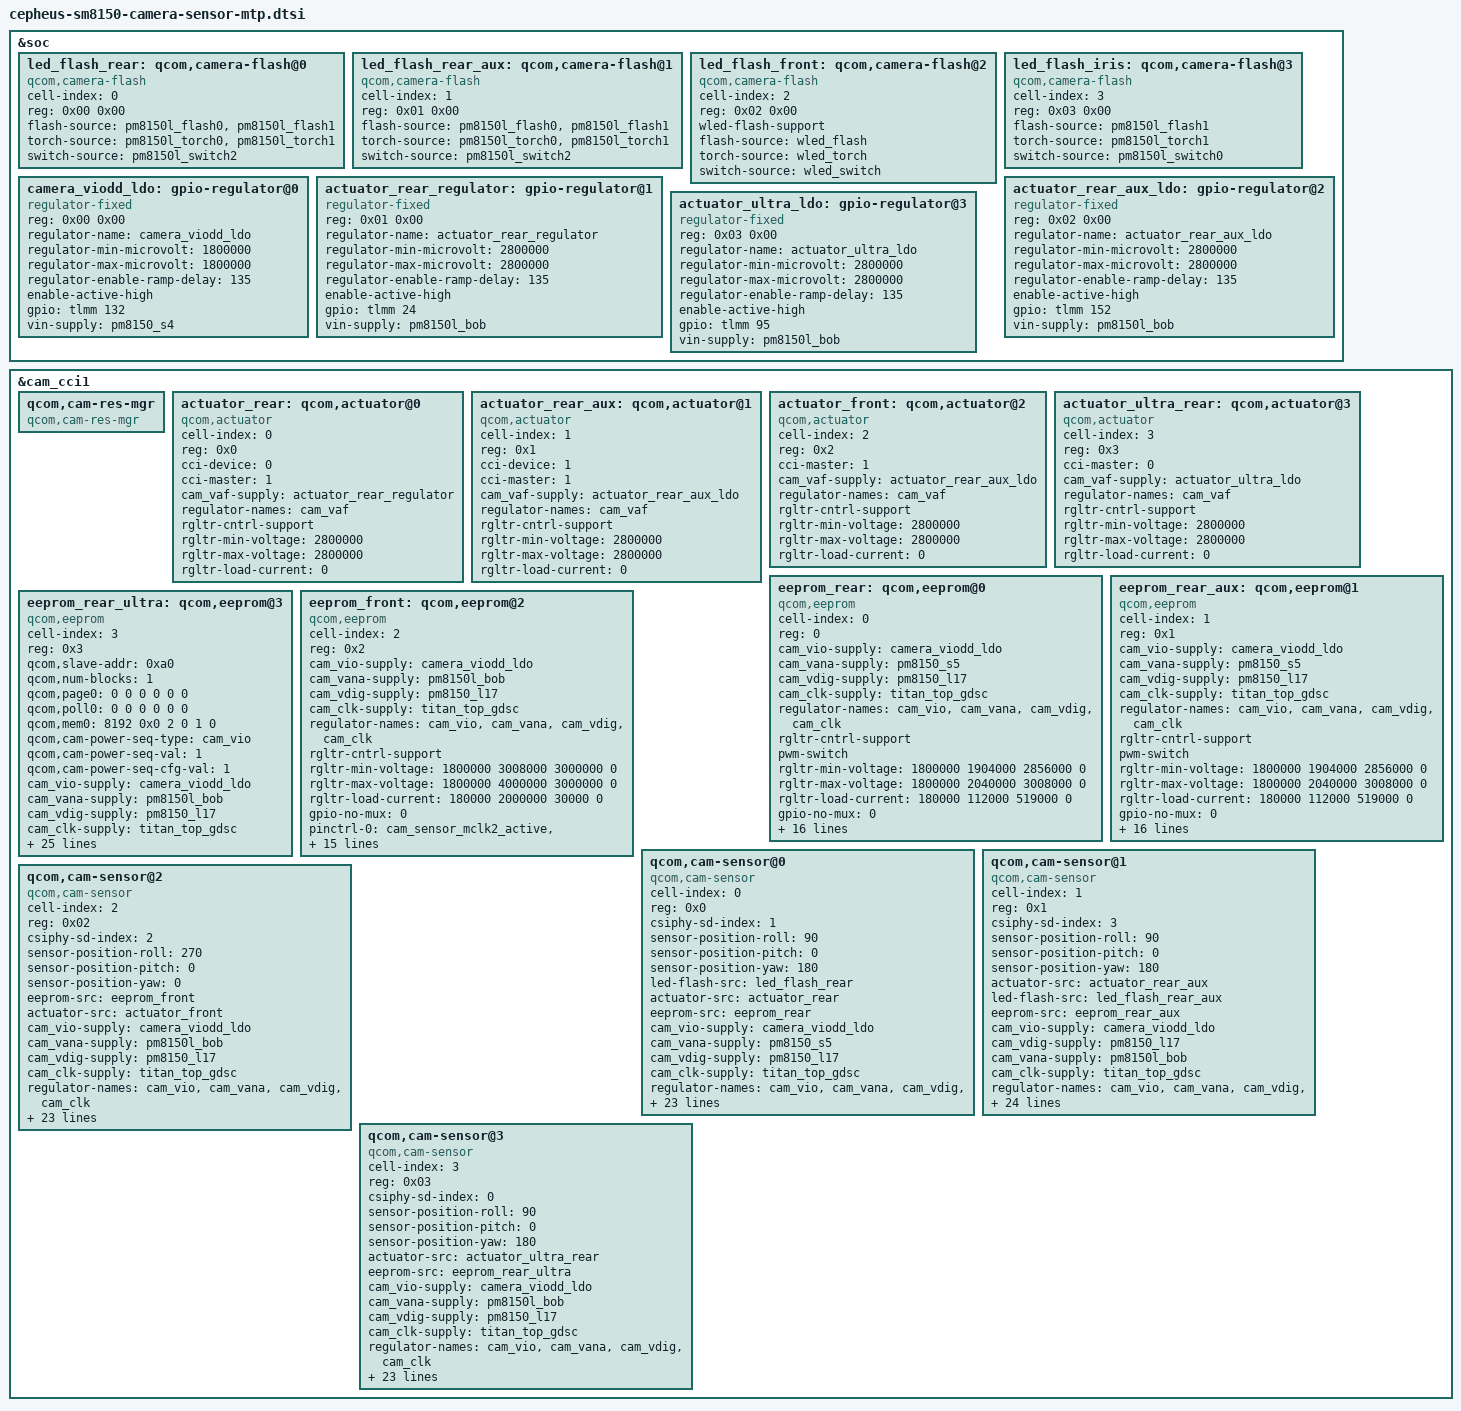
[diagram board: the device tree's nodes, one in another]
/*
 * Copyright (c) 2018, The Linux Foundation. All rights reserved.
 * Copyright (C) 2019 XiaoMi, Inc.
 *
 * This program is free software; you can redistribute it and/or modify
 * it under the terms of the GNU General Public License version 2 and
 * only version 2 as published by the Free Software Foundation.
 *
 * This program is distributed in the hope that it will be useful,
 * but WITHOUT ANY WARRANTY; without even the implied warranty of
 * MERCHANTABILITY or FITNESS FOR A PARTICULAR PURPOSE.  See the
 * GNU General Public License for more details.
 */

&soc {
	led_flash_rear: qcom,camera-flash@0 {
		cell-index = <0>;
		reg = <0x00 0x00>;
		compatible = "qcom,camera-flash";
		flash-source = <&pm8150l_flash0 &pm8150l_flash1>;
		torch-source = <&pm8150l_torch0 &pm8150l_torch1>;
		switch-source = <&pm8150l_switch2>;
		status = "ok";
	};

	led_flash_rear_aux: qcom,camera-flash@1 {
		cell-index = <1>;
		reg = <0x01 0x00>;
		compatible = "qcom,camera-flash";
		flash-source = <&pm8150l_flash0 &pm8150l_flash1>;
		torch-source = <&pm8150l_torch0 &pm8150l_torch1>;
		switch-source = <&pm8150l_switch2>;
		status = "ok";
	};

	led_flash_front: qcom,camera-flash@2 {
		cell-index = <2>;
		reg = <0x02 0x00>;
		compatible = "qcom,camera-flash";
		wled-flash-support;
		flash-source = <&wled_flash>;
		torch-source = <&wled_torch>;
		switch-source = <&wled_switch>;
		status = "ok";
	};

	led_flash_iris: qcom,camera-flash@3 {
		cell-index = <3>;
		reg = <0x03 0x00>;
		compatible = "qcom,camera-flash";
		flash-source = <&pm8150l_flash1>;
		torch-source = <&pm8150l_torch1>;
		switch-source = <&pm8150l_switch0>;
		status = "ok";
	};

	camera_viodd_ldo: gpio-regulator@0 {
		compatible = "regulator-fixed";
		reg = <0x00 0x00>;
		regulator-name = "camera_viodd_ldo";
		regulator-min-microvolt = <1800000>;
		regulator-max-microvolt = <1800000>;
		regulator-enable-ramp-delay = <135>;
		enable-active-high;
		gpio = <&tlmm 132 0>;
		vin-supply = <&pm8150_s4>;
	};

	actuator_rear_regulator: gpio-regulator@1 {
		compatible = "regulator-fixed";
		reg = <0x01 0x00>;
		regulator-name = "actuator_rear_regulator";
		regulator-min-microvolt = <2800000>;
		regulator-max-microvolt = <2800000>;
		regulator-enable-ramp-delay = <135>;
		enable-active-high;
		gpio = <&tlmm 24 0>;
		vin-supply = <&pm8150l_bob>;
	};

	actuator_rear_aux_ldo: gpio-regulator@2 {
		compatible = "regulator-fixed";
		reg = <0x02 0x00>;
		regulator-name = "actuator_rear_aux_ldo";
		regulator-min-microvolt = <2800000>;
		regulator-max-microvolt = <2800000>;
		regulator-enable-ramp-delay = <135>;
		enable-active-high;
		gpio = <&tlmm 152 0>;
		vin-supply = <&pm8150l_bob>;
	};

	actuator_ultra_ldo: gpio-regulator@3 {
		compatible = "regulator-fixed";
		reg = <0x03 0x00>;
		regulator-name = "actuator_ultra_ldo";
		regulator-min-microvolt = <2800000>;
		regulator-max-microvolt = <2800000>;
		regulator-enable-ramp-delay = <135>;
		enable-active-high;
		gpio = <&tlmm 95 0>;
		vin-supply = <&pm8150l_bob>;
	};
};

&cam_cci1 {
	qcom,cam-res-mgr {
		compatible = "qcom,cam-res-mgr";
		status = "ok";
	};

	actuator_rear: qcom,actuator@0 {
		cell-index = <0>;
		reg = <0x0>;
		compatible = "qcom,actuator";
		cci-device = <0>;
		cci-master = <1>;
		cam_vaf-supply = <&actuator_rear_regulator>;
		regulator-names = "cam_vaf";
		rgltr-cntrl-support;
		rgltr-min-voltage = <2800000>;
		rgltr-max-voltage = <2800000>;
		rgltr-load-current = <0>;
	};

	actuator_rear_aux: qcom,actuator@1 {
		cell-index = <1>;
		reg = <0x1>;
		compatible = "qcom,actuator";
		cci-device = <1>;
		cci-master = <1>;
		cam_vaf-supply = <&actuator_rear_aux_ldo>;
		regulator-names = "cam_vaf";
		rgltr-cntrl-support;
		rgltr-min-voltage = <2800000>;
		rgltr-max-voltage = <2800000>;
		rgltr-load-current = <0>;
	};

	actuator_front: qcom,actuator@2 {
		cell-index = <2>;
		reg = <0x2>;
		compatible = "qcom,actuator";
		cci-master = <1>;
		cam_vaf-supply = <&actuator_rear_aux_ldo>;
		regulator-names = "cam_vaf";
		rgltr-cntrl-support;
		rgltr-min-voltage = <2800000>;
		rgltr-max-voltage = <2800000>;
		rgltr-load-current = <0>;
	};

	actuator_ultra_rear: qcom,actuator@3 {
		cell-index = <3>;
		reg = <0x3>;
		compatible = "qcom,actuator";
		cci-master = <0>;
		cam_vaf-supply = <&actuator_ultra_ldo>;
		regulator-names = "cam_vaf";
		rgltr-cntrl-support;
		rgltr-min-voltage = <2800000>;
		rgltr-max-voltage = <2800000>;
		rgltr-load-current = <0>;
	};

	eeprom_rear: qcom,eeprom@0 {
		cell-index = <0>;
		reg = <0>;
		compatible = "qcom,eeprom";
		cam_vio-supply = <&camera_viodd_ldo>;
		cam_vana-supply = <&pm8150_s5>;
		cam_vdig-supply = <&pm8150_l17>;
		cam_clk-supply = <&titan_top_gdsc>;
		regulator-names = "cam_vio", "cam_vana", "cam_vdig",
		      "cam_clk";
		rgltr-cntrl-support;
		pwm-switch;
		rgltr-min-voltage = <1800000 1904000 2856000 0>;
		rgltr-max-voltage = <1800000 2040000 3008000 0>;
		rgltr-load-current = <180000 112000 519000 0>;
		gpio-no-mux = <0>;
		pinctrl-names = "cam_default", "cam_suspend";
		pinctrl-0 = <&cam_sensor_mclk1_active
				&cam_sensor_active_rear>;
		pinctrl-1 = <&cam_sensor_mclk1_suspend
				&cam_sensor_suspend_rear>;
		gpios = <&tlmm 14 0>,
			<&tlmm 30 0>,
			<&tlmm 59 0>;
		gpio-reset = <1>;
		gpio-vdig = <2>;
		gpio-req-tbl-num = <0 1 2>;
		gpio-req-tbl-flags = <1 0 0>;
		gpio-req-tbl-label = "CAMIF_MCLK0",
					"CAM_RESET0",
					"CAM_VDIG0";
		sensor-mode = <0>;
		cci-master = <1>;
		status = "ok";
		clocks = <&clock_camcc CAM_CC_MCLK1_CLK>;
		clock-names = "cam_clk";
		clock-cntl-level = "turbo";
		clock-rates = <19200000>;
	};

	eeprom_rear_aux: qcom,eeprom@1 {
		cell-index = <1>;
		reg = <0x1>;
		compatible = "qcom,eeprom";
		cam_vio-supply = <&camera_viodd_ldo>;
		cam_vana-supply = <&pm8150_s5>;
		cam_vdig-supply = <&pm8150_l17>;
		cam_clk-supply = <&titan_top_gdsc>;
		regulator-names = "cam_vio", "cam_vana", "cam_vdig",
		      "cam_clk";
		rgltr-cntrl-support;
		pwm-switch;
		rgltr-min-voltage = <1800000 1904000 2856000 0>;
		rgltr-max-voltage = <1800000 2040000 3008000 0>;
		rgltr-load-current = <180000 112000 519000 0>;
		gpio-no-mux = <0>;
		pinctrl-names = "cam_default", "cam_suspend";
		pinctrl-0 = <&cam_sensor_mclk1_active
				&cam_sensor_active_rear>;
		pinctrl-1 = <&cam_sensor_mclk1_suspend
				&cam_sensor_suspend_rear>;
		gpios = <&tlmm 14 0>,
			<&tlmm 30 0>,
			<&tlmm 59 0>;
		gpio-reset = <1>;
		gpio-vdig = <2>;
		gpio-req-tbl-num = <0 1 2>;
		gpio-req-tbl-flags = <1 0 0>;
		gpio-req-tbl-label = "CAMIF_MCLK0",
					"CAM_RESET0",
					"CAM_VDIG0";
		sensor-mode = <0>;
		cci-master = <1>;
		status = "ok";
		clocks = <&clock_camcc CAM_CC_MCLK1_CLK>;
		clock-names = "cam_clk";
		clock-cntl-level = "turbo";
		clock-rates = <19200000>;
	};

	eeprom_rear_ultra: qcom,eeprom@3 {
		cell-index = <3>;
		reg = <0x3>;

		compatible = "qcom,eeprom";
		qcom,slave-addr = <0xa0>;
		qcom,num-blocks = <1>;
		qcom,page0 = <0 0 0 0 0 0 >;
		qcom,poll0 = <0 0 0 0 0 0>;
		qcom,mem0 = <8192 0x0 2 0 1 0>;
		qcom,cam-power-seq-type = "cam_vio";
		qcom,cam-power-seq-val = <1>;
		qcom,cam-power-seq-cfg-val = <1>;
		cam_vio-supply = <&camera_viodd_ldo>;
		cam_vana-supply = <&pm8150l_bob>;
		cam_vdig-supply = <&pm8150_l17>;
		cam_clk-supply = <&titan_top_gdsc>;
		regulator-names = "cam_vio", "cam_vana", "cam_vdig",
			"cam_clk";
		rgltr-cntrl-support;
		rgltr-min-voltage = <1800000 3008000 2856000 0>;
		rgltr-max-voltage = <1800000 4000000 3000000 0>;
		rgltr-load-current = <180000 2000000 300000 0>;
		gpio-no-mux = <0>;
		pinctrl-names = "cam_default", "cam_suspend";
		pinctrl-0 = <&cam_sensor_mclk0_active
				 &cam_sensor_active_iris>;
		pinctrl-1 = <&cam_sensor_mclk0_suspend
				 &cam_sensor_suspend_iris>;
		gpios = <&tlmm 13 0>,
			<&tlmm 28 0>,
			<&tlmm 94 0>;
		gpio-reset = <1>;
		gpio-vana = <2>;
		gpio-req-tbl-num = <0 1 2>;
		gpio-req-tbl-flags = <1 0 0>;
		gpio-req-tbl-label = "CAMIF_MCLK3",
				 "CAM_RESET3",
				 "CAM_VDIG3";
		sensor-position = <0>;
		sensor-mode = <0>;
		cci-device = <0>;
		cci-master = <0>;
		status = "ok";
		clocks = <&clock_camcc CAM_CC_MCLK0_CLK>;
		clock-names = "cam_clk";
		clock-cntl-level = "turbo";
		clock-rates = <19200000>;
	};

	eeprom_front: qcom,eeprom@2 {
		cell-index = <2>;
		reg = <0x2>;
		compatible = "qcom,eeprom";
		cam_vio-supply = <&camera_viodd_ldo>;
		cam_vana-supply = <&pm8150l_bob>;
		cam_vdig-supply = <&pm8150_l17>;
		cam_clk-supply = <&titan_top_gdsc>;
		regulator-names = "cam_vio", "cam_vana", "cam_vdig",
							"cam_clk";
		rgltr-cntrl-support;
		rgltr-min-voltage = <1800000 3008000 3000000 0>;
		rgltr-max-voltage = <1800000 4000000 3000000 0>;
		rgltr-load-current = <180000 2000000 30000 0>;
		gpio-no-mux = <0>;
		pinctrl-names = "cam_default", "cam_suspend";
		pinctrl-0 = <&cam_sensor_mclk2_active
						&cam_sensor_active_front>;
		pinctrl-1 = <&cam_sensor_mclk2_suspend
						&cam_sensor_suspend_front>;
		gpios = <&tlmm 15 0>,
			<&tlmm 54 0>,

			<&tlmm 118 0>;
		gpio-reset = <1>;
		gpio-req-tbl-num = <0 1>;
		gpio-req-tbl-flags = <1 0>;
		gpio-req-tbl-label = "CAMIF_MCLK2",
				"CAM_RESET2";
		sensor-position = <1>;
		sensor-mode = <0>;
		cci-device = <1>;
		cci-master = <1>;
		status = "ok";
		clocks = <&clock_camcc CAM_CC_MCLK2_CLK>;
		clock-names = "cam_clk";
		clock-cntl-level = "turbo";
		clock-rates = <19200000>;
	};

	qcom,cam-sensor@0 {
		cell-index = <0>;
		compatible = "qcom,cam-sensor";
		reg = <0x0>;
		csiphy-sd-index = <1>;
		sensor-position-roll = <90>;
		sensor-position-pitch = <0>;
		sensor-position-yaw = <180>;
		led-flash-src = <&led_flash_rear>;
		actuator-src = <&actuator_rear>;
		eeprom-src = <&eeprom_rear>;
		cam_vio-supply = <&camera_viodd_ldo>;
		cam_vana-supply = <&pm8150_s5>;
		cam_vdig-supply = <&pm8150_l17>;
		cam_clk-supply = <&titan_top_gdsc>;
		regulator-names = "cam_vio", "cam_vana", "cam_vdig",
			 "cam_clk";
		rgltr-cntrl-support;
		pwm-switch;
		rgltr-min-voltage = <1800000 1904000 2856000 0>;
		rgltr-max-voltage = <1800000 2040000 3008000 0>;
		rgltr-load-current = <180000 112000 519000 0>;
		gpio-no-mux = <0>;
		pinctrl-names = "cam_default", "cam_suspend";
		pinctrl-0 = <&cam_sensor_mclk1_active
				&cam_sensor_active_rear>;
		pinctrl-1 = <&cam_sensor_mclk1_suspend
				&cam_sensor_suspend_rear>;
		gpios = <&tlmm 14 0>,
			<&tlmm 30 0>,
			<&tlmm 59 0>;
		gpio-reset = <1>;
		gpio-vdig = <2>;
		gpio-req-tbl-num = <0 1 2>;
		gpio-req-tbl-flags = <1 0 0>;
		gpio-req-tbl-label = "CAMIF_MCLK0",
					"CAM_RESET0",
					"CAM_VDIG0";
		sensor-mode = <0>;
		cci-master = <1>;
		status = "ok";
		clocks = <&clock_camcc CAM_CC_MCLK1_CLK>;
		clock-names = "cam_clk";
		clock-cntl-level = "turbo";
		clock-rates = <19200000>;
	};


	qcom,cam-sensor@1 {
		cell-index = <1>;
		compatible = "qcom,cam-sensor";
		reg = <0x1>;
		csiphy-sd-index = <3>;
		sensor-position-roll = <90>;
		sensor-position-pitch = <0>;
		sensor-position-yaw = <180>;
		actuator-src = <&actuator_rear_aux>;
		led-flash-src = <&led_flash_rear_aux>;
		eeprom-src = <&eeprom_rear_aux>;
		cam_vio-supply = <&camera_viodd_ldo>;
		cam_vdig-supply = <&pm8150_l17>;
		cam_vana-supply = <&pm8150l_bob>;
		cam_clk-supply = <&titan_top_gdsc>;
		regulator-names = "cam_vio", "cam_vana", "cam_vdig",
			"cam_clk";
		rgltr-cntrl-support;
		pwm-switch;
		rgltr-min-voltage = <1800000 3008000 3000000 0>;
		rgltr-max-voltage = <1800000 4000000 3000000 0>;
		rgltr-load-current = <180000 2000000 300000 0>;
		gpio-no-mux = <0>;
		pinctrl-names = "cam_default", "cam_suspend";
		pinctrl-0 = <&cam_sensor_mclk3_active
				&cam_sensor_active_rear_aux>;
		pinctrl-1 = <&cam_sensor_mclk3_suspend
				&cam_sensor_suspend_rear_aux>;
		gpios = <&tlmm 16 0>,
			<&tlmm 23 0>,
			<&tlmm 29 0>;
		gpio-reset = <1>;
		gpio-vana = <2>;
		gpio-req-tbl-num = <0 1 2>;
		gpio-req-tbl-flags = <1 0 0>;
		gpio-req-tbl-label = "CAMIF_MCLK1",
					"CAM_RESET1",
					"CAM_VANA1";
		sensor-mode = <0>;
		cci-device = <1>;
		cci-master = <1>;
		status = "ok";
		clocks = <&clock_camcc CAM_CC_MCLK3_CLK>;
		clock-names = "cam_clk";
		clock-cntl-level = "turbo";
		clock-rates = <19200000>;
	};


	qcom,cam-sensor@2 {
		cell-index = <2>;
		compatible = "qcom,cam-sensor";
		reg = <0x02>;
		csiphy-sd-index = <2>;
		sensor-position-roll = <270>;
		sensor-position-pitch = <0>;
		sensor-position-yaw = <0>;
		eeprom-src = <&eeprom_front>;
		actuator-src = <&actuator_front>;

		cam_vio-supply = <&camera_viodd_ldo>;

		cam_vana-supply = <&pm8150l_bob>;
		cam_vdig-supply = <&pm8150_l17>;
		cam_clk-supply = <&titan_top_gdsc>;
		regulator-names = "cam_vio", "cam_vana", "cam_vdig",
			"cam_clk";
		rgltr-cntrl-support;
		pwm-switch;
		rgltr-min-voltage = <1800000 3008000 3000000 0>;
		rgltr-max-voltage = <1800000 4000000 3000000 0>;
		rgltr-load-current = <180000 2000000 30000 0>;
		gpio-no-mux = <0>;
		pinctrl-names = "cam_default", "cam_suspend";
		pinctrl-0 = <&cam_sensor_mclk2_active
				 &cam_sensor_active_front>;
		pinctrl-1 = <&cam_sensor_mclk2_suspend
				 &cam_sensor_suspend_front>;
		gpios = <&tlmm 15 0>,
			<&tlmm 54 0>,

			<&tlmm 118 0>;
		gpio-reset = <1>;
		gpio-vana = <2>;
		gpio-req-tbl-num = <0 1 2>;
		gpio-req-tbl-flags = <1 0 0>;
		gpio-req-tbl-label = "CAMIF_MCLK2",
					"CAM_RESET2",
					"CAM_VANA2";
		sensor-mode = <0>;
		cci-device = <1>;
		cci-master = <1>;
		status = "ok";
		clocks = <&clock_camcc CAM_CC_MCLK2_CLK>;
		clock-names = "cam_clk";
		clock-cntl-level = "turbo";
		clock-rates = <19200000>;
	};

qcom,cam-sensor@3 {
		cell-index = <3>;
		compatible = "qcom,cam-sensor";
		reg = <0x03>;
		csiphy-sd-index = <0>;
		sensor-position-roll = <90>;
		sensor-position-pitch = <0>;
		sensor-position-yaw = <180>;
		actuator-src = <&actuator_ultra_rear>;
		eeprom-src = <&eeprom_rear_ultra>;

		cam_vio-supply = <&camera_viodd_ldo>;

		cam_vana-supply = <&pm8150l_bob>;
		cam_vdig-supply = <&pm8150_l17>;
		cam_clk-supply = <&titan_top_gdsc>;
		regulator-names = "cam_vio", "cam_vana", "cam_vdig",
			"cam_clk";
		rgltr-cntrl-support;
		pwm-switch;
		rgltr-min-voltage = <1800000 3008000 2856000 0>;
		rgltr-max-voltage = <1800000 4000000 3000000 0>;
		rgltr-load-current = <180000 2000000 300000 0>;
		gpio-no-mux = <0>;
		pinctrl-names = "cam_default", "cam_suspend";
		pinctrl-0 = <&cam_sensor_mclk0_active
				 &cam_sensor_active_iris>;
		pinctrl-1 = <&cam_sensor_mclk0_suspend
				 &cam_sensor_suspend_iris>;
		gpios = <&tlmm 13 0>,
			<&tlmm 28 0>,
			<&tlmm 94 0>;
		gpio-reset = <1>;
		gpio-vana = <2>;
		gpio-req-tbl-num = <0 1 2>;
		gpio-req-tbl-flags = <1 0 0>;
		gpio-req-tbl-label = "CAMIF_MCLK3",
					"CAM_RESET3",
					"CAM_VDIG3";
		sensor-mode = <0>;
		cci-device = <0>;
		cci-master = <0>;
		status = "ok";
		clocks = <&clock_camcc CAM_CC_MCLK0_CLK>;
		clock-names = "cam_clk";
		clock-cntl-level = "turbo";
		clock-rates = <19200000>;
	};
};


